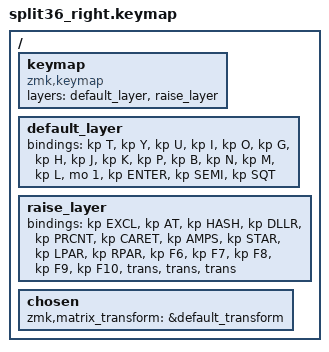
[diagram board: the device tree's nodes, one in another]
/ {
  keymap {
    compatible = "zmk,keymap";
    layers = <&default_layer &raise_layer>;
  };

  default_layer {
    bindings = <
      &kp T     &kp Y     &kp U     &kp I     &kp O
      &kp G     &kp H     &kp J     &kp K     &kp P
      &kp B     &kp N     &kp M     &kp L     &mo 1
      &kp ENTER &kp SEMI  &kp SQT
    >;
  };

  raise_layer {
    bindings = <
      &kp EXCL  &kp AT    &kp HASH  &kp DLLR  &kp PRCNT
      &kp CARET &kp AMPS  &kp STAR  &kp LPAR  &kp RPAR
      &kp F6    &kp F7    &kp F8    &kp F9    &kp F10
      &trans    &trans    &trans
    >;
  };
};
/ {
  chosen {
    zmk,matrix_transform = &default_transform;
  };
};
